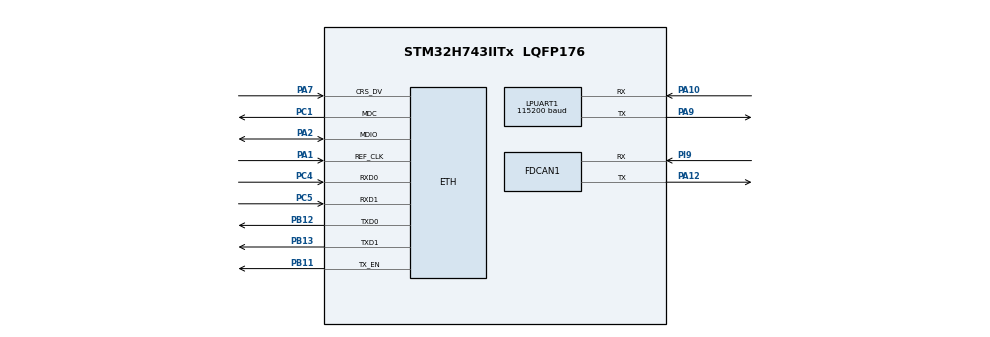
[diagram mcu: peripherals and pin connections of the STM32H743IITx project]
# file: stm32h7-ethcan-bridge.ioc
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CORTEX_M7.AccessPermission_S-Cortex_Memory_Protection_Unit_Region1_Settings_S=MPU_REGION_FULL_ACCESS
CORTEX_M7.BaseAddress_S-Cortex_Memory_Protection_Unit_Region1_Settings_S=0x30000000
CORTEX_M7.CPU_DCache=Enabled
CORTEX_M7.CPU_ICache=Enabled
CORTEX_M7.DisableExec_S-Cortex_Memory_Protection_Unit_Region1_Settings_S=MPU_INSTRUCTION_ACCESS_DISABLE
CORTEX_M7.Enable_S-Cortex_Memory_Protection_Unit_Region1_Settings_S=MPU_REGION_ENABLE
CORTEX_M7.Enable_Spec=__NULL
CORTEX_M7.IsShareable_S-Cortex_Memory_Protection_Unit_Region1_Settings_S=MPU_ACCESS_SHAREABLE
CORTEX_M7.MPU_Control=MPU_PRIVILEGED_DEFAULT
CORTEX_M7.Size_S-Cortex_Memory_Protection_Unit_Region1_Settings_S=MPU_REGION_SIZE_128KB
CORTEX_M7.TypeExtField_S-Cortex_Memory_Protection_Unit_Region1_Settings_S=MPU_TEX_LEVEL1
CORTEX_M7.default_mode_Activation=1
ETH.MediaInterface=HAL_ETH_RMII_MODE
FDCAN1.CalculateBaudRateNominal=500000
FDCAN1.CalculateTimeBitNominal=2000
FDCAN1.CalculateTimeQuantumNominal=100.0
FDCAN1.DataPrescaler=12
FDCAN1.DataTimeSeg1=15
FDCAN1.DataTimeSeg2=4
FDCAN1.ExtFiltersNbr=1
FDCAN1.NominalPrescaler=12
FDCAN1.NominalTimeSeg1=15
FDCAN1.NominalTimeSeg2=4
FDCAN1.RxFifo0ElmtsNbr=32
FDCAN1.StdFiltersNbr=1
FDCAN1.TxFifoQueueElmtsNbr=32
FREERTOS.Tasks01=defaultTask,24,1024,StartDefaultTask,Default,NULL,Dynamic,NULL,NULL
FREERTOS.configMINIMAL_STACK_SIZE=1024
FREERTOS.configTOTAL_HEAP_SIZE=65536
LPUART1.BaudRate=115200
LWIP.BSP.number=1
LWIP.IP_ADDRESS=192.168.001.100
LWIP.LWIP_DHCP=0
LWIP.MEM_SIZE=65536
LWIP.NETMASK_ADDRESS=255.255.255.000
LWIP.Version=v2.1.2_Cube
LWIP0.BSP.STBoard=false
LWIP0.BSP.api=BSP_COMPONENT_DRIVER
LWIP0.BSP.component=LAN8742
LWIP0.BSP.instance=LAN8742
LWIP0.BSP.name=Driver_PHY
LWIP0.BSP.semaphore=S_LAN8742
LWIP0.BSP.solution=LAN8742
Mcu.Family=STM32H7
Mcu.Name=STM32H743IITx
Mcu.Package=LQFP176
NVIC.ETH_IRQn=true\:5\:0\:false\:false\:true\:true\:true\:true\:true
NVIC.FDCAN1_IT0_IRQn=true\:5\:0\:false\:false\:true\:true\:true\:true\:true
NVIC.PriorityGroup=NVIC_PRIORITYGROUP_4
NVIC.TIM8_UP_TIM13_IRQn=true\:15\:0\:false\:false\:true\:false\:false\:true\:true
NVIC.TimeBase=TIM8_UP_TIM13_IRQn
NVIC.TimeBaseIP=TIM8
PA1.Mode=RMII
PA1.Signal=ETH_REF_CLK
PA10.Mode=Asynchronous
PA10.Signal=LPUART1_RX
PA12.Mode=FDCAN_Activate
PA12.Signal=FDCAN1_TX
PA13\ (JTMS/SWDIO).Mode=Serial_Wire
PA13\ (JTMS/SWDIO).Signal=DEBUG_JTMS-SWDIO
PA14\ (JTCK/SWCLK).Mode=Serial_Wire
PA14\ (JTCK/SWCLK).Signal=DEBUG_JTCK-SWCLK
PA2.Mode=RMII
PA2.Signal=ETH_MDIO
PA7.Mode=RMII
PA7.Signal=ETH_CRS_DV
PA9.Mode=Asynchronous
PA9.Signal=LPUART1_TX
PB11.Mode=RMII
PB11.Signal=ETH_TX_EN
PB12.Mode=RMII
PB12.Signal=ETH_TXD0
PB13.Mode=RMII
PB13.Signal=ETH_TXD1
PC1.Mode=RMII
PC1.Signal=ETH_MDC
PC4.Mode=RMII
PC4.Signal=ETH_RXD0
PC5.Mode=RMII
PC5.Signal=ETH_RXD1
PH0-OSC_IN\ (PH0).Mode=HSE-External-Oscillator
PH0-OSC_IN\ (PH0).Signal=RCC_OSC_IN
PH1-OSC_OUT\ (PH1).Mode=HSE-External-Oscillator
PH1-OSC_OUT\ (PH1).Signal=RCC_OSC_OUT
PI9.Mode=FDCAN_Activate
PI9.Signal=FDCAN1_RX
ProjectManager.HeapSize=0x200
ProjectManager.StackSize=0x400
ProjectManager.TargetToolchain=CMake
RCC.ADCFreq_Value=50390625
RCC.APB1Freq_Value=120000000
RCC.APB2Freq_Value=120000000
RCC.APB3Freq_Value=120000000
RCC.APB4Freq_Value=120000000
RCC.CortexFreq_Value=480000000
RCC.D1PPRE=RCC_APB3_DIV2
RCC.D2PPRE1=RCC_APB1_DIV2
RCC.D2PPRE2=RCC_APB2_DIV2
RCC.D3PPRE=RCC_APB4_DIV2
RCC.DIVM1=5
RCC.DIVN1=192
RCC.DIVQ1=8
RCC.HCLKFreq_Value=240000000
RCC.HPRE=RCC_HCLK_DIV2
RCC.PLLFRACN=0
RCC.PLLSourceVirtual=RCC_PLLSOURCE_HSE
RCC.SYSCLKFreq_VALUE=480000000
RCC.SYSCLKSource=RCC_SYSCLKSOURCE_PLLCLK
RCC.USBFreq_Value=120000000
TIM17.AutoReloadPreload=TIM_AUTORELOAD_PRELOAD_ENABLE
TIM17.Period=999
TIM17.Prescaler=479
VP_FREERTOS_VS_CMSIS_V2.Mode=CMSIS_V2
VP_LWIP_VS_Enabled.Mode=Enabled
VP_MEMORYMAP_VS_MEMORYMAP.Mode=CurAppReg
VP_RNG_VS_RNG.Mode=RNG_Activate
VP_SYS_VS_tim8.Mode=TIM8
VP_TIM17_VS_ClockSourceINT.Mode=Enable_Timer
VP_wolfSSL.I-CUBE-wolfMQTT_VS_wolfMQTTJjwolfMQTT_1.19.2_1.19.2.Mode=wolfMQTTJjwolfMQTT
VP_wolfSSL.I-CUBE-wolfSSL_VS_wolfSSLJjwolfSSL_5.8.2_5.8.2.Mode=wolfSSLJjwolfSSL
board=custom
wolfSSL.I-CUBE-wolfMQTT.1.19.2.WOLFMQTT_CONF_FREERTOS=1
wolfSSL.I-CUBE-wolfMQTT.1.19.2.WOLFMQTT_CONF_TLS=1
wolfSSL.I-CUBE-wolfMQTT.1.19.2.wolfMQTTCcwolfMQTTJjwolfMQTTJjCore=true
wolfSSL.I-CUBE-wolfMQTT.1.19.2.wolfMQTTCcwolfMQTTJjwolfMQTTJjTLS=true
wolfSSL.I-CUBE-wolfSSL.5.8.2.WOLF_CONF_CHAPOLY=0
wolfSSL.I-CUBE-wolfSSL.5.8.2.WOLF_CONF_KYBER=0
wolfSSL.I-CUBE-wolfSSL.5.8.2.WOLF_CONF_RTOS=2
wolfSSL.I-CUBE-wolfSSL.5.8.2.WOLF_CONF_TEST=0
wolfSSL.I-CUBE-wolfSSL.5.8.2.WOLF_CONF_WOLFCRYPT_ONLY=0
wolfSSL.I-CUBE-wolfSSL.5.8.2.wolfSSLCcwolfSSLJjwolfCryptJjCore=true
wolfSSL.I-CUBE-wolfSSL.5.8.2.wolfSSLCcwolfSSLJjwolfSSLJjCore=true

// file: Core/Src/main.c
/* USER CODE BEGIN Header */
/**
  ******************************************************************************
  * @file           : main.c
  * @brief          : Main program body
  ******************************************************************************
  * @attention
  *
  * Copyright (c) 2025 STMicroelectronics.
  * All rights reserved.
  *
  * This software is licensed under terms that can be found in the LICENSE file
  * in the root directory of this software component.
  * If no LICENSE file comes with this software, it is provided AS-IS.
  *
  ******************************************************************************
  */
/* USER CODE END Header */
#include "main.h"
#include "cmsis_os.h"
#include "lwip.h"

/* USER CODE BEGIN Includes */
#include "string.h"
#include "stdio.h"
#include "print_output.h"
#include "mqtt_client.h"
#include "can_ctrl.h"
/* USER CODE END Includes */

FDCAN_HandleTypeDef hfdcan1;

UART_HandleTypeDef hlpuart1;

RNG_HandleTypeDef hrng;

TIM_HandleTypeDef htim17;

/* Definitions for defaultTask */
osThreadId_t defaultTaskHandle;
const osThreadAttr_t defaultTask_attributes = {
  .name = "defaultTask",
  .stack_size = 1024 * 4,
  .priority = (osPriority_t) osPriorityNormal,
};
/* USER CODE BEGIN PV */
mqtt_client_handle_t mqtt_handle;
const char *topic = "stm32/canopen/data";
can_ctrl_handle_t can_ctrl;  // CANopen controller
/* USER CODE END PV */

void SystemClock_Config(void);
static void MPU_Config(void);
static void MX_GPIO_Init(void);
static void MX_LPUART1_UART_Init(void);
static void MX_RNG_Init(void);
static void MX_FDCAN1_Init(void);
static void MX_TIM17_Init(void);
void StartDefaultTask(void *argument);

int main(void)
{

  /* MPU Configuration--------------------------------------------------------*/
  MPU_Config();

  /* Enable the CPU Cache */

  /* Enable I-Cache---------------------------------------------------------*/
  SCB_EnableICache();

  /* Enable D-Cache---------------------------------------------------------*/
  SCB_EnableDCache();

  /* MCU Configuration--------------------------------------------------------*/

  /* Reset of all peripherals, Initializes the Flash interface and the Systick. */
  HAL_Init();

  /* Configure the system clock */
  SystemClock_Config();

  /* Initialize all configured peripherals */
  MX_GPIO_Init();
  MX_LPUART1_UART_Init();
  MX_RNG_Init();
  MX_FDCAN1_Init();
  MX_TIM17_Init();

  /* Init scheduler */
  osKernelInitialize();

  /* Create the thread(s) */
  /* creation of defaultTask */
  defaultTaskHandle = osThreadNew(StartDefaultTask, NULL, &defaultTask_attributes);

  /* Start scheduler */
  osKernelStart();

  /* We should never get here as control is now taken by the scheduler */

  /* Infinite loop */
  while (1)
  {

  }
}

void SystemClock_Config(void)
{
  RCC_OscInitTypeDef RCC_OscInitStruct = {0};
  RCC_ClkInitTypeDef RCC_ClkInitStruct = {0};

  /** Supply configuration update enable
  */
  HAL_PWREx_ConfigSupply(PWR_LDO_SUPPLY);

  /** Configure the main internal regulator output voltage
  */
  __HAL_PWR_VOLTAGESCALING_CONFIG(PWR_REGULATOR_VOLTAGE_SCALE0);

  while(!__HAL_PWR_GET_FLAG(PWR_FLAG_VOSRDY)) {}

  /** Initializes the RCC Oscillators according to the specified parameters
  * in the RCC_OscInitTypeDef structure.
  */
  RCC_OscInitStruct.OscillatorType = RCC_OSCILLATORTYPE_HSI48|RCC_OSCILLATORTYPE_HSE;
  RCC_OscInitStruct.HSEState = RCC_HSE_ON;
  RCC_OscInitStruct.HSI48State = RCC_HSI48_ON;
  RCC_OscInitStruct.PLL.PLLState = RCC_PLL_ON;
  RCC_OscInitStruct.PLL.PLLSource = RCC_PLLSOURCE_HSE;
  RCC_OscInitStruct.PLL.PLLM = 5;
  RCC_OscInitStruct.PLL.PLLN = 192;
  RCC_OscInitStruct.PLL.PLLP = 2;
  RCC_OscInitStruct.PLL.PLLQ = 8;
  RCC_OscInitStruct.PLL.PLLR = 2;
  RCC_OscInitStruct.PLL.PLLRGE = RCC_PLL1VCIRANGE_2;
  RCC_OscInitStruct.PLL.PLLVCOSEL = RCC_PLL1VCOWIDE;
  RCC_OscInitStruct.PLL.PLLFRACN = 0;
  if (HAL_RCC_OscConfig(&RCC_OscInitStruct) != HAL_OK)
  {
    Error_Handler();
  }

  /** Initializes the CPU, AHB and APB buses clocks
  */
  RCC_ClkInitStruct.ClockType = RCC_CLOCKTYPE_HCLK|RCC_CLOCKTYPE_SYSCLK
                              |RCC_CLOCKTYPE_PCLK1|RCC_CLOCKTYPE_PCLK2
                              |RCC_CLOCKTYPE_D3PCLK1|RCC_CLOCKTYPE_D1PCLK1;
  RCC_ClkInitStruct.SYSCLKSource = RCC_SYSCLKSOURCE_PLLCLK;
  RCC_ClkInitStruct.SYSCLKDivider = RCC_SYSCLK_DIV1;
  RCC_ClkInitStruct.AHBCLKDivider = RCC_HCLK_DIV2;
  RCC_ClkInitStruct.APB3CLKDivider = RCC_APB3_DIV2;
  RCC_ClkInitStruct.APB1CLKDivider = RCC_APB1_DIV2;
  RCC_ClkInitStruct.APB2CLKDivider = RCC_APB2_DIV2;
  RCC_ClkInitStruct.APB4CLKDivider = RCC_APB4_DIV2;

  if (HAL_RCC_ClockConfig(&RCC_ClkInitStruct, FLASH_LATENCY_4) != HAL_OK)
  {
    Error_Handler();
  }
}

static void MX_FDCAN1_Init(void)
{

  hfdcan1.Instance = FDCAN1;
  hfdcan1.Init.FrameFormat = FDCAN_FRAME_CLASSIC;
  hfdcan1.Init.Mode = FDCAN_MODE_NORMAL;
  hfdcan1.Init.AutoRetransmission = DISABLE;
  hfdcan1.Init.TransmitPause = DISABLE;
  hfdcan1.Init.ProtocolException = DISABLE;
  hfdcan1.Init.NominalPrescaler = 12;
  hfdcan1.Init.NominalSyncJumpWidth = 1;
  hfdcan1.Init.NominalTimeSeg1 = 15;
  hfdcan1.Init.NominalTimeSeg2 = 4;
  hfdcan1.Init.DataPrescaler = 12;
  hfdcan1.Init.DataSyncJumpWidth = 1;
  hfdcan1.Init.DataTimeSeg1 = 15;
  hfdcan1.Init.DataTimeSeg2 = 4;
  hfdcan1.Init.MessageRAMOffset = 0;
  hfdcan1.Init.StdFiltersNbr = 1;
  hfdcan1.Init.ExtFiltersNbr = 1;
  hfdcan1.Init.RxFifo0ElmtsNbr = 32;
  hfdcan1.Init.RxFifo0ElmtSize = FDCAN_DATA_BYTES_8;
  hfdcan1.Init.RxFifo1ElmtsNbr = 0;
  hfdcan1.Init.RxFifo1ElmtSize = FDCAN_DATA_BYTES_8;
  hfdcan1.Init.RxBuffersNbr = 0;
  hfdcan1.Init.RxBufferSize = FDCAN_DATA_BYTES_8;
  hfdcan1.Init.TxEventsNbr = 0;
  hfdcan1.Init.TxBuffersNbr = 0;
  hfdcan1.Init.TxFifoQueueElmtsNbr = 32;
  hfdcan1.Init.TxFifoQueueMode = FDCAN_TX_FIFO_OPERATION;
  hfdcan1.Init.TxElmtSize = FDCAN_DATA_BYTES_8;
  if (HAL_FDCAN_Init(&hfdcan1) != HAL_OK)
  {
    Error_Handler();
  }

}

static void MX_LPUART1_UART_Init(void)
{

  hlpuart1.Instance = LPUART1;
  hlpuart1.Init.BaudRate = 115200;
  hlpuart1.Init.WordLength = UART_WORDLENGTH_8B;
  hlpuart1.Init.StopBits = UART_STOPBITS_1;
  hlpuart1.Init.Parity = UART_PARITY_NONE;
  hlpuart1.Init.Mode = UART_MODE_TX_RX;
  hlpuart1.Init.HwFlowCtl = UART_HWCONTROL_NONE;
  hlpuart1.Init.OneBitSampling = UART_ONE_BIT_SAMPLE_DISABLE;
  hlpuart1.Init.ClockPrescaler = UART_PRESCALER_DIV1;
  hlpuart1.AdvancedInit.AdvFeatureInit = UART_ADVFEATURE_NO_INIT;
  hlpuart1.FifoMode = UART_FIFOMODE_DISABLE;
  if (HAL_UART_Init(&hlpuart1) != HAL_OK)
  {
    Error_Handler();
  }
  if (HAL_UARTEx_SetTxFifoThreshold(&hlpuart1, UART_TXFIFO_THRESHOLD_1_8) != HAL_OK)
  {
    Error_Handler();
  }
  if (HAL_UARTEx_SetRxFifoThreshold(&hlpuart1, UART_RXFIFO_THRESHOLD_1_8) != HAL_OK)
  {
    Error_Handler();
  }
  if (HAL_UARTEx_DisableFifoMode(&hlpuart1) != HAL_OK)
  {
    Error_Handler();
  }

}

static void MX_RNG_Init(void)
{

  hrng.Instance = RNG;
  hrng.Init.ClockErrorDetection = RNG_CED_ENABLE;
  if (HAL_RNG_Init(&hrng) != HAL_OK)
  {
    Error_Handler();
  }

}

static void MX_TIM17_Init(void)
{

  htim17.Instance = TIM17;
  htim17.Init.Prescaler = 479;
  htim17.Init.CounterMode = TIM_COUNTERMODE_UP;
  htim17.Init.Period = 999;
  htim17.Init.ClockDivision = TIM_CLOCKDIVISION_DIV1;
  htim17.Init.RepetitionCounter = 0;
  htim17.Init.AutoReloadPreload = TIM_AUTORELOAD_PRELOAD_ENABLE;
  if (HAL_TIM_Base_Init(&htim17) != HAL_OK)
  {
    Error_Handler();
  }

}

static void MX_GPIO_Init(void)
{

  /* GPIO Ports Clock Enable */
  __HAL_RCC_GPIOI_CLK_ENABLE();
  __HAL_RCC_GPIOH_CLK_ENABLE();
  __HAL_RCC_GPIOC_CLK_ENABLE();
  __HAL_RCC_GPIOA_CLK_ENABLE();
  __HAL_RCC_GPIOB_CLK_ENABLE();

}

  /*
    Run mosquitto broker locally for testing:
        .\mosquitto.exe -c test.conf -v
        .\mosquitto_sub.exe -h 192.168.1.200 -t "#" -v

    test.conf:
        listener 1883 0.0.0.0
        allow_anonymous true
  */
void StartDefaultTask(void *argument)
{
  print_output_init(&hlpuart1);
  printf("=== STM32H7 CANopen-MQTT Bridge ===\n");

  MX_LWIP_Init();

  struct netif *netif = netif_list;
  print_output_netif_info(netif);

  // MQTT setup
  ip_addr_t target_ip;
  IP4_ADDR(&target_ip, 192, 168, 1, 200);
  mqtt_client_init(&mqtt_handle, &target_ip, "STM32_CANopen");

  // CANopen setup - monitor remote nodes
  uint8_t remote_nodes[] = {10, 11};  // Example: monitor nodes 10 and 11
  can_ctrl_status_t status = can_ctrl_init(&can_ctrl, &hfdcan1, &htim17,
                                           remote_nodes, 2);

  if (status != CAN_CTRL_OK)
  {
      printf("ERROR: CANopen init failed with status %d\n", status);
      Error_Handler();
  }

  printf("CANopen controller initialized\n");
  printf("Monitoring remote nodes: %d, %d\n", remote_nodes[0], remote_nodes[1]);

  uint32_t counter = 0;
  uint32_t last_publish_time = 0;
  const uint32_t publish_interval_ms = 1000;  // Publish every 1 second

  for(;;)
  {
    // MQTT connection handling
    if (!mqtt_client_is_connected(mqtt_handle.client))
    {
        if (mqtt_client_connect_process(&mqtt_handle) != ERR_OK)
        {
            osDelay(100);
            continue;
        }
    }

    mqtt_client_check_timeout(&mqtt_handle);

    // Wait for CANopen to be operational
    if (!can_ctrl_is_operational(&can_ctrl))
    {
        if (counter % 50 == 0) // Print every 5 seconds
        {
            uint8_t nmt_state = can_ctrl_get_nmt_state(&can_ctrl);
            printf("Waiting for CANopen operational state (current: %d)...\n", nmt_state);
        }
        counter++;
        osDelay(100);
        continue;
    }

    // Publish PDO data via MQTT periodically
    uint32_t current_time = HAL_GetTick();
    if (mqtt_handle.is_connected &&
        !mqtt_handle.pub_in_progress &&
        (current_time - last_publish_time >= publish_interval_ms))
    {
        // Get PDO data from first remote node
        can_ctrl_resp_t resp;
        if (can_ctrl_get_pdo_data(&can_ctrl, remote_nodes[0], &resp) == CAN_CTRL_OK)
        {
            // Format data for MQTT
            char payload[64];
            snprintf(payload, sizeof(payload),
                    "Node%d: %02X %02X %02X %02X %02X %02X %02X %02X",
                    remote_nodes[0],
                    resp.pdo_data.data[0], resp.pdo_data.data[1],
                    resp.pdo_data.data[2], resp.pdo_data.data[3],
                    resp.pdo_data.data[4], resp.pdo_data.data[5],
                    resp.pdo_data.data[6], resp.pdo_data.data[7]);

            err_t err = mqtt_client_publish(&mqtt_handle, topic, payload);
            if (err == ERR_OK)
            {
                printf("MQTT: Published PDO data #%lu\n", counter++);
                last_publish_time = current_time;
            }
        }
        else
        {
            printf("No PDO data from node %d yet\n", remote_nodes[0]);
        }
    }

    osDelay(100);
  }
}

 /* MPU Configuration */

void MPU_Config(void)
{
  MPU_Region_InitTypeDef MPU_InitStruct = {0};

  /* Disables the MPU */
  HAL_MPU_Disable();

  /** Initializes and configures the Region and the memory to be protected
  */
  MPU_InitStruct.Enable = MPU_REGION_ENABLE;
  MPU_InitStruct.BaseAddress = 0x30000000;
  MPU_InitStruct.Size = MPU_REGION_SIZE_128KB;
  MPU_InitStruct.SubRegionDisable = 0x0;
  MPU_InitStruct.TypeExtField = MPU_TEX_LEVEL1;
  MPU_InitStruct.AccessPermission = MPU_REGION_FULL_ACCESS;
  MPU_InitStruct.DisableExec = MPU_INSTRUCTION_ACCESS_DISABLE;
  MPU_InitStruct.IsShareable = MPU_ACCESS_SHAREABLE;
  MPU_InitStruct.IsCacheable = MPU_ACCESS_NOT_CACHEABLE;
  MPU_InitStruct.IsBufferable = MPU_ACCESS_NOT_BUFFERABLE;

  HAL_MPU_ConfigRegion(&MPU_InitStruct);
  /* Enables the MPU */
  HAL_MPU_Enable(MPU_PRIVILEGED_DEFAULT);

}

void HAL_TIM_PeriodElapsedCallback(TIM_HandleTypeDef *htim)
{
  /* USER CODE BEGIN Callback 0 */
  if (htim->Instance == TIM17)
  {
    can_ctrl_timer_interrupt(&can_ctrl);
  }
  /* USER CODE END Callback 0 */
  if (htim->Instance == TIM8)
  {
    HAL_IncTick();
  }
}

void Error_Handler(void)
{
  __disable_irq();
  while (1)
  {
  }
}
